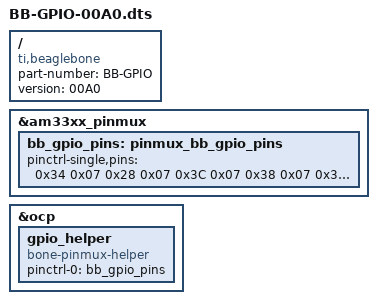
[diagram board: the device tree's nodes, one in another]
/dts-v1/;
/plugin/;
 
/ {
    compatible = "ti,beaglebone", "ti,beaglebone-black";
    part-number = "BB-GPIO";
    version = "00A0";
 
    fragment@0 {
        target = <&am33xx_pinmux>;
        __overlay__ {
             bb_gpio_pins: pinmux_bb_gpio_pins {
                 pinctrl-single,pins =  <
                    0x34 0x07
                    0x28 0x07
                    0x3C 0x07
                    0x38 0x07
                    0x30 0x07
                    0x2c 0x07
                   /* 0x34 0x37 Zarezerwowany dla w1 master*/
                  >;
             };
        };
    };
 
    fragment@1 {
        target = <&ocp>;
        __overlay__ {
            gpio_helper {
                status          = "okay";
                compatible      = "bone-pinmux-helper";
                pinctrl-names   = "default";
                pinctrl-0       = <&bb_gpio_pins>;
            };
        };
    };
};
